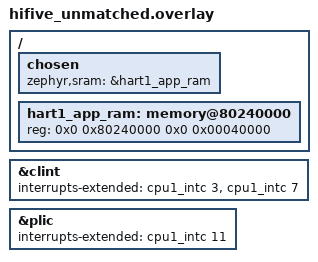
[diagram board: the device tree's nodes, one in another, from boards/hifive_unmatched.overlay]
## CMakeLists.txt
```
cmake_minimum_required(VERSION 3.20.0)
find_package(Zephyr REQUIRED HINTS $ENV{ZEPHYR_BASE})
project(hart1_zephyr_app)

set(APP_ROOT ${CMAKE_CURRENT_SOURCE_DIR}/..)
set(USE_HALO 0 CACHE STRING "Build Zephyr Hart1 with HALO-generated sources")

if(DEFINED ENV{COMMON_DIR} AND NOT "$ENV{COMMON_DIR}" STREQUAL "")
  set(COMMON_DIR $ENV{COMMON_DIR})
else()
  set(COMMON_DIR ${APP_ROOT}/../../src/common)
endif()

if(USE_HALO)
  set(DEPS_DIR ${APP_ROOT}/deps/halo/codegen/riscv64_h1_zephyr)
else()
  set(DEPS_DIR ${APP_ROOT}/deps/classical)
endif()

file(GLOB DEPS_SRCS ${DEPS_DIR}/src/*.c)
file(GLOB COMMON_SRCS ${COMMON_DIR}/*.c)
file(GLOB BATTERY_SRCS ${APP_ROOT}/../../src/battery/*.c)
file(GLOB BMS_SRCS ${APP_ROOT}/../../src/bms/*.c)

target_sources(app PRIVATE src/main.c ${DEPS_SRCS} ${COMMON_SRCS} ${BATTERY_SRCS} ${BMS_SRCS})
target_include_directories(app PRIVATE src ${DEPS_DIR}/include ${COMMON_DIR} ${APP_ROOT}/../../src/battery ${APP_ROOT}/../../src/bms ${APP_ROOT}/../../src)
target_compile_definitions(app PRIVATE USE_HALO=${USE_HALO})
```

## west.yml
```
# The west manifest file for upstream Zephyr.
#
# The per-installation west configuration file, .west/config, sets the
# path to the project containing this file in the [manifest] section's
# "path" variable.
#
# You are free to create your own manifest files and put them in any
# repository you want, to create your own custom Zephyr installations.
# For example, you could create a manifest file in your own out of
# tree application directory, which would pull this zephyr repository
# in as an ordinary project.
#
# You can pass your manifest repositories to west init when creating a
# new Zephyr installation. See the west documentation for more
# information.

manifest:
  defaults:
    remote: upstream

  remotes:
    - name: upstream
      url-base: https://github.com/zephyrproject-rtos

  group-filter: [-optional]

  #
  # Please add items below based on alphabetical order
  projects:
    - name: open-amp
      revision: 76d2168bcdfcd23a9a7dce8c21f2083b90a1e60a
      path: modules/lib/open-amp
    - name: picolibc
      path: modules/lib/picolibc
      revision: 764ef4e401a8f4c6a86ab723533841f072885a5b
    - name: zcbor
      revision: 75d088037eb237b18e7ec1f47c9ce494b9b95aab
      path: modules/lib/zcbor

  self:
    path: zephyr
    west-commands: scripts/west-commands.yml
    import: submanifests
```

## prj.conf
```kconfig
# Ensure system clock exists for timer APIs
CONFIG_SYS_CLOCK_EXISTS=y
CONFIG_SERIAL=y
CONFIG_CONSOLE=y
CONFIG_UART_CONSOLE=y
CONFIG_PRINTK=y
CONFIG_CBPRINTF_FP_SUPPORT=y
CONFIG_MINIMAL_LIBC=y
# CONFIG_PICOLIBC is not set
CONFIG_TIMER=y
CONFIG_SYS_CLOCK_TICKS_PER_SEC=1000
# Minimal configuration for RISC-V
CONFIG_HEAP_MEM_POOL_SIZE=0
```

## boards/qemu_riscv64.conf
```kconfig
CONFIG_RV_BOOT_HART=1
CONFIG_SYS_CLOCK_EXISTS=y
```

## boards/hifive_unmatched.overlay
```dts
/ {
	chosen {
		/*
		 * Align the active Zephyr image with the legacy Hart 1 UART loader
		 * path used by Hart 0, which copies app1.bin to 0x80240000 and
		 * starts hart 1 from that address.
		 */
		zephyr,sram = &hart1_app_ram;
	};

	hart1_app_ram: memory@80240000 {
		device_type = "memory";
		reg = <0x0 0x80240000 0x0 0x00040000>;
		reg-names = "mem";
	};
};

&clint {
	interrupts-extended = <&cpu1_intc 3 &cpu1_intc 7>;
};

&plic {
	interrupts-extended = <&cpu1_intc 11>;
};
```

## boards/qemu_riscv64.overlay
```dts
/ {
	chosen {
		/*
		 * Align the Zephyr image with the custom Hart 0 UART loader used
		 * in the QEMU multihart flow. Hart 0 copies app1.bin to 0x80240000
		 * and starts hart 1 from that address.
		 */
		zephyr,sram = &hart1_app_ram;
	};
};

hart1_app_ram: memory@80240000 {
	device_type = "memory";
	reg = <0x80240000 0x00040000>;
};

&mtimer {
	status = "okay";
	interrupts-extended = <&cpu1_intc 7>;
};

&clint {
	interrupts-extended = <&cpu1_intc 3 &cpu1_intc 7>;
};

&plic {
	interrupts-extended = <&cpu1_intc 11>;
};
```

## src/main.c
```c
/**
 *                                                                                               
 *      ▄▄▄▄                                            ▄▄▄▄▄▄                 ▀                 
 *     █▀   ▀  ▄▄▄   ▄ ▄▄    ▄▄▄    ▄▄▄    ▄ ▄▄         █      ▄   ▄   ▄▄▄   ▄▄▄     ▄▄▄   ▄ ▄▄  
 *     ▀█▄▄▄  █▀  █  █▀  █  █   ▀  █▀ ▀█   █▀  ▀        █▄▄▄▄▄ █   █  █   ▀    █    █▀ ▀█  █▀  █ 
 *         ▀█ █▀▀▀▀  █   █   ▀▀▀▄  █   █   █            █      █   █   ▀▀▀▄    █    █   █  █   █ 
 *     ▀▄▄▄█▀ ▀█▄▄▀  █   █  ▀▄▄▄▀  ▀█▄█▀   █            █      ▀▄▄▀█  ▀▄▄▄▀  ▄▄█▄▄  ▀█▄█▀  █   █ 
 *                                                                                               
 *                                                                                               
 */

/************************* INCLUDE SECTION *************************/
#include <zephyr/kernel.h>
#include "workshop_protocol.h"
#include "console_lock.h"
#include "bms.h"
#if !defined(USE_HALO) || (USE_HALO == 0)
    #include "classical_api.h"
#else
    #include "halo_api.h"
#endif

/************************* GLOBAL SECTION *************************/

//TODO Classical: 0. Define SensorFrame structure based on the workshop specification only for the classical implementation!. 

/************************* FUNCTION SECTION *************************/
int main( void )
{

// Classical implementation
#if !defined(USE_HALO) || (USE_HALO == 0)

/*

        - Call BMS APIs to get the sensor data and fill the SensorFrame struct with the data. 
            -- Example:
                SensorFrame frame;
                frame.battery_voltage_mv = (uint32_t)(bms_get_voltage());
                frame.charge_current_ma = (int32_t)(bms_get_current());
                frame.battery_temp_c = bms_get_temperature();
                frame.breaker_closed = bms_get_breaker_closed();
                frame.fault_flags = bms_get_fault_flags();

        - Publish/log/send the SensorFrame to the peer using shared memory access (write to defined memory address for SensorFrame)
            -- Synchronization is important, so make sure to implement a simple protocol to signal when new data is available for the peer to read.

        - Log the Info to the console using printk("[APP1] ") which is behaving similar to printf
            -- [APP1] needs to be included in the log message to differentiate logs from other applications running on different harts
            -- Use logging on change to avoid flooding the console with repeated messages. 
            -- For example, only log when data changes, or every N cycles.

            -- Example log messages:
                Received command if mode changes:
                    printk( "[APP1] Charging mode=%s\n",
                            command.charging_mode );

                Every N cycles:
                    printk( "[APP1] sent mV=%u mA=%d temp=%f breaker_closed=%u faults=%d\n",
                            ( unsigned int ) frame.battery_voltage_mv,
                            frame.charge_current_ma,
                            frame.battery_temp_c,
                            ( unsigned int ) frame.breaker_closed,
                            ( unsigned int ) frame.fault_flags );

        - Use k_msleep( ms ) to create a delay in the loop
    */


    // Variables to read user command to BMS
    uint32_t bms_cmd_id = 0U;
    uint32_t bms_cmd_param = 0U;

    typedef struct  {
        unsigned int battery_voltage_mv;
        int charge_current_ma;  
        float battery_temp_c;
        unsigned int fault_flags; 
        bool breaker_closed;
        bool status_bit; // Sync with memory
    } SensorFrameIf;

    /*TODO Classical: 1. Declare a variable of type SensorFrame */
    SensorFrameIf sensor_frame;

    /*2. Declare a variable of type SensorFrame to hold the last sent sensor data for logging on change */
    uint32_t heartbeat_counter = 0U;
    SensorFrameIf *sensor_frame_ptr = (SensorFrameIf *)(SENSOR_FRAME_BASE);


    // Init BMS controller
    bms_init();

    while( 1 )
    {
        // Read command for BMS from console and apply it to BMS
        bms_get_operator_command( &bms_cmd_id, &bms_cmd_param );
        // Apply operator command to BMS
        command_bms( bms_cmd_id, bms_cmd_param ); 

        /*TODO Classical: 3. Call BMS APIs to get the sensor data and fill the SensorFrame struct with the data. 
            -- sensor_frame is a placeholder variable, it is a type of SensorFrame struct that you will define based on the workshop specification
        */
        sensor_frame.battery_voltage_mv = (uint32_t)(bms_get_voltage());
        sensor_frame.charge_current_ma = (int32_t)(bms_get_current());
        sensor_frame.battery_temp_c = bms_get_temperature();
        sensor_frame.breaker_closed = bms_get_breaker_closed();
        sensor_frame.fault_flags = bms_get_fault_flags();


        /*TODO Classical: 4. Publish/log/send the SensorFrame to the peer using shared memory access (write to defined memory address for SensorFrame)
            -- SENSOR_FRAME_BASE is a memory address where the SensorFrame will be written
            -- Synchronization is important, so make sure to implement a simple protocol to signal when new data is available for the peer to read.
        */
        
        sensor_frame_ptr->status_bit = 1;
        sensor_frame.status_bit = 0;
        sensor_frame_ptr->battery_temp_c = sensor_frame.battery_temp_c;
        sensor_frame_ptr->battery_voltage_mv = sensor_frame.battery_voltage_mv;
        sensor_frame_ptr->breaker_closed = sensor_frame.breaker_closed;
        sensor_frame_ptr->charge_current_ma =sensor_frame.charge_current_ma;
        sensor_frame_ptr->fault_flags = sensor_frame.fault_flags;
        sensor_frame_ptr->status_bit = sensor_frame.status_bit;

        if( ( heartbeat_counter % 10U ) == 0U || sensor_frame.fault_flags != 0U )
        {
            printk( "[APP1] CC sent mV=%u mA=%d temp=%f breaker_closed=%u faults=%d\n",
                       ( unsigned int ) sensor_frame_ptr->battery_voltage_mv,
                       sensor_frame_ptr->charge_current_ma,
                       sensor_frame_ptr->battery_temp_c,
                       ( unsigned int ) sensor_frame_ptr->breaker_closed,
                       ( unsigned int ) sensor_frame_ptr->fault_flags );
        }

        heartbeat_counter++;
        k_msleep( WORKSHOP_SENSOR_PERIOD_MS );
    }
#else // HALO implementation

/*
    * Workshop steps for implementing the safety monitor loop:
    * 1. Declare a variable of type SensorFrame generated from HALO
      - SensorFrame struct is available from HALO generated code from deps/halo/codegen/riscv64_h1_zephyr/include/halo_structs.h

    * 2. In a while loop in which the sensor fusion will run continuously:

        - Call BMS APIs to get the sensor data and fill the SensorFrame struct with the data. 
            -- Example:
                SensorFrame frame;
                frame.battery_voltage_mv = (unsigned int)(bms_get_voltage());
                frame.charge_current_ma = (int)(bms_get_current());
                frame.battery_temp_c = bms_get_temperature();
                frame.breaker_closed = bms_get_breaker_closed();
                frame.fault_flags = bms_get_fault_flags();

        - Send the SensorFrame to the peer using halo_send_ API functions defined in halo_api.h
            -- Check the return value of halo_send_ function to ensure the message was sent successfully if not sent log an error message    
                printk( "[APP1] SensorFrame send failed\n" );
            -- Full path is in .deps/halo/codegen/riscv64_h1_zephyr/include/halo_api.h and deps/halo/codegen/riscv64_h1_zephyr/src/halo_channels.c

        - Log the Info to the console using printk("[APP1] ") which is behaving similar to printf
            -- [APP1] needs to be included in the log message to differentiate logs from other applications running on different harts
            -- Use logging on change to avoid flooding the console with repeated messages. 
            -- For example, only log when data changes, or every N cycles.

            -- Example log messages:
                Received command if mode changes:
                    printk( "[APP1] Charging mode=%s\n",
                            command.charging_mode );

                Every N cycles:
                    printk( "[APP1] sent mV=%u mA=%d temp=%f breaker_closed=%u faults=%d\n",
                            ( unsigned int ) frame.battery_voltage_mv,
                            frame.charge_current_ma,
                            frame.battery_temp_c,
                            ( unsigned int ) frame.breaker_closed,
                            ( unsigned int ) frame.fault_flags );

        - Use k_msleep( ms ) to create a delay in the loop
    */



    /* TODO HALO: 1. Initialize the HALO channels for communication with the peer using init function defined in halo_api.c
         - This will set up the necessary channels for sending and receiving messages with the peer
            -- Full path to init function is in .deps/halo/codegen/riscv64_h1_zephyr/src/halo_api.c
    */

    // 2. Declare hearbeat_counter that increments on each loop iteration.
    uint32_t heartbeat_counter = 0U;
    // Variables to read user command to BMS
    uint32_t bms_cmd_id = 0U;
    uint32_t bms_cmd_param = 0U;

    /* TODO HALO: 2. Declare a variable of type SensorFrame generated from HALO
      - SensorFrame struct is available from HALO generated code from deps/halo/codegen/riscv64_h1_zephyr/include/halo_structs.h
    */


    // Init BMS controller
    bms_init();

    while( 1 )
    {

        /* This is a demo loop to showcase the application running */
        /* TODO HALO: 3. This is for demonstration purposes only and should be deleted when workshop code is written */
        if( ( heartbeat_counter % 20U ) == 0U)
        {
            printk( "[APP1] HALO demo loop\n" );
        }
    
        // Read command for BMS from console and apply it to BMS
        bms_get_operator_command( &bms_cmd_id, &bms_cmd_param );
        // Apply operator command to BMS
        command_bms( bms_cmd_id, bms_cmd_param ); 

        /*TODO HALO: 4. Call BMS APIs to get the sensor data and fill the SensorFrame struct with the data. 
            -- sensor_frame is a placeholder variable, it is a type of SensorFrame struct that you will define based on the workshop specification
        */
        // sensor_frame.battery_voltage_mv = (unsigned int)(bms_get_voltage());
        // sensor_frame.charge_current_ma = (int)(bms_get_current());
        // sensor_frame.battery_temp_c = bms_get_temperature();
        // sensor_frame.breaker_closed = bms_get_breaker_closed();
        // sensor_frame.fault_flags = bms_get_fault_flags();
 
        /*TODO HALO: 5. Send the SensorFrame to the peer using halo_send_ API functions defined in halo_api.h
            -- Check the return value of halo_send_ function to ensure the message was sent successfully if not sent log an error message    
                printk( "[APP1] SensorFrame send failed\n" );
            -- Full path is in .deps/halo/codegen/riscv64_h1_zephyr/include/halo_api.h and deps/halo/codegen/riscv64_h1_zephyr/src/halo_channels.c
        */


        /*TODO HALO: 6. Log the Info to the console using printk("[APP1] ") which is behaving similar to printf */
        // sensor_frame is a placeholder variable, it is a type of SensorFrame struct that you will define based on the workshop specification
        // if( ( heartbeat_counter % 10 ) == 0U)
        // {
        //     printk( "[APP1] sent mV=%u mA=%d temp=%f breaker_closed=%u faults=%d\n",
        //                ( unsigned int ) sensor_frame.battery_voltage_mv,
        //                sensor_frame.charge_current_ma,
        //                sensor_frame.battery_temp_c,
        //                ( unsigned int ) sensor_frame.breaker_closed,
        //                ( unsigned int ) sensor_frame.fault_flags );
        // }

        heartbeat_counter++;
        k_msleep( WORKSHOP_SENSOR_PERIOD_MS );
    }
#endif

    return 0;
}
```
